# PY32F003xx register map
Vendor: Puya; Series: PY32F0; File version: 1.0.0
CPU: CM0+ r0p1, little endian, no MPU, no FPU, 4 interrupt priority bits
Registers are 32-bit, read-write, reset 0x0 unless marked. A register's access mark holds for its fields unless they carry their own. Offsets are from the block's base; [hi:lo] are bit positions.

## IWDG — Independent watchdog
Base 0x40003000
0x00 KR wo — Key register (IWDG_KR)
  [15:0] KEY — Key value
0x04 PR — Prescaler register (IWDG_PR)
  [2:0] PR — Prescaler divider
    1=0; 2=1; 4=2
0x08 RLR reset 0xFFF — Reload register (IWDG_RLR)
  [11:0] RL — Watchdog counter reloadvalue
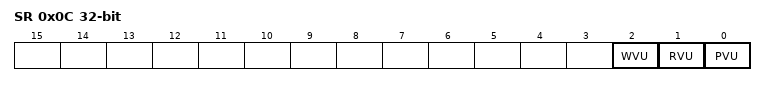
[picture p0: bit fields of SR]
0x0C SR ro — Status register (IWDG_SR)
  [2] WVU — Watchdog counter window value update
  [1] RVU — Watchdog counter reload valueupdate
  [0] PVU — Watchdog prescaler valueupdate
0x10 WINR ro — Window register (IWDG_SR)
  [11:0] WIN — window counter

## LPTIM — Low power timer
Base 0x40007C00
0x00 ISR ro — Interrupt and Status Register
  [1] ARRM — Autoreload match
0x04 ICR wo — Interrupt Clear Register
  [1] ARRMCF — Autoreload match ClearFlag
0x08 IER — Interrupt Enable Register
  [1] ARRMIE — Autoreload match InterruptEnable
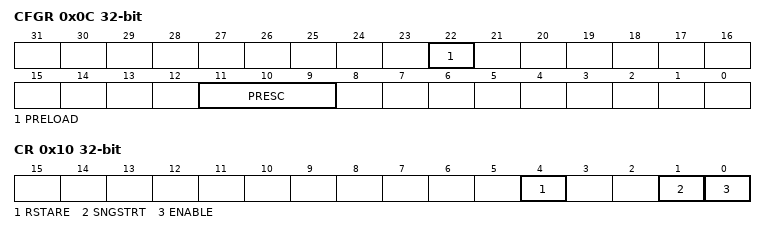
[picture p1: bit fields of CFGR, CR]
0x0C CFGR — Configuration Register
  [22] PRELOAD — Registers update mode
  [11:9] PRESC — Clock prescaler
    1=0; 2=1; 4=2
0x10 CR — Control Register
  [4] RSTARE — Reset after read enable
  [1] SNGSTRT — LPTIM start in single mode
  [0] ENABLE — LPTIM Enable
0x18 ARR reset 0x1 — Autoreload Register
  [15:0] ARR — Auto reload value
0x1C CNT ro — Counter Register
  [15:0] CNT — Counter value

## PWR — Power control
Base 0x40007000
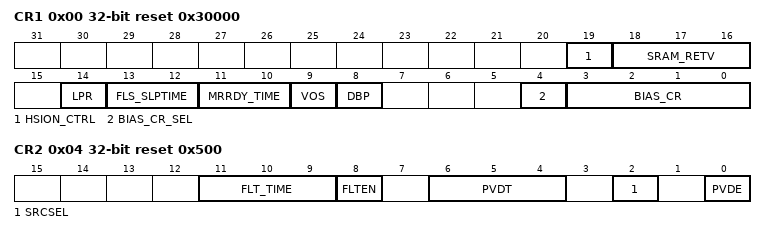
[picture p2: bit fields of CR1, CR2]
0x00 CR1 reset 0x30000 — Power control register 1
  [19] HSION_CTRL — HSI open time control
  [18:16] SRAM_RETV — SRAM retention voltage control
    1=0; 2=1; 4=2
  [14] LPR — Low-power run
  [13:12] FLS_SLPTIME — Flash wait time after wakeup from the stop mode
    1=0; 2=1
  [11:10] MRRDY_TIME — Time selection wakeup from LP to VR
    1=0; 2=1
  [9] VOS — Voltage scaling rangeselection
  [8] DBP — Disable backup domain writeprotection
  [4] BIAS_CR_SEL — MR Bias current selection
  [3:0] BIAS_CR — MR Bias current
    1=0; 2=1; 4=2; 8=3
0x04 CR2 reset 0x500 — Power control register 2
  [11:9] FLT_TIME — Digital filter time configuration
    1=0; 2=1; 4=2
  [8] FLTEN — Digital filter enable
  [6:4] PVDT — Power voltage detector thresholdselection
    1=0; 2=1; 4=2
  [2] SRCSEL — Power voltage detector volatageselection
  [0] PVDE — Power voltage detectorenable
0x14 SR ro — Power status register
  [11] PVDO — PVD output

## RTC — Real time clock
Base 0x40002800
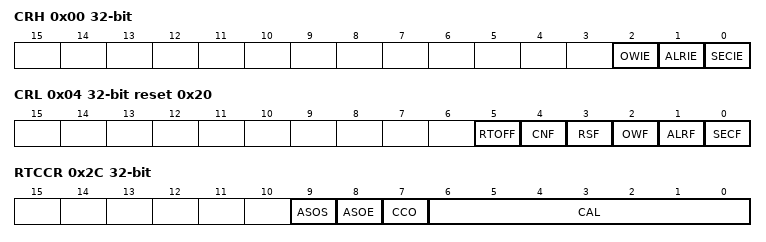
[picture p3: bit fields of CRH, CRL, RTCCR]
0x00 CRH — RTC Control Register High
  [2] OWIE — Overflow interrupt Enable
  [1] ALRIE — Alarm interrupt Enable
  [0] SECIE — Second interrupt Enable
0x04 CRL reset 0x20 — RTC Control Register Low
  [5] RTOFF ro — RTC operation OFF
  [4] CNF — Configuration Flag
  [3] RSF — Registers Synchronized Flag
  [2] OWF — Overflow Flag
  [1] ALRF — Alarm Flag
  [0] SECF — Second Flag
0x08 PRLH wo — RTC Prescaler Load Register High
  [3:0] PRLH
0x0C PRLL wo reset 0x8000 — RTC Prescaler Load Register Low
  [15:0] PRLL — RTC Prescaler Divider Register Low
0x10 DIVH ro — RTC Prescaler Divider Register High
  [3:0] DIVH — RTC prescaler divider register high
0x14 DIVL ro reset 0x8000 — RTC Prescaler Divider Register Low
  [15:0] DIVL — RTC prescaler divider register Low
0x18 CNTH — RTC Counter Register High
  [15:0] CNTH — RTC counter register high
0x1C CNTL — RTC Counter Register Low
  [15:0] CNTL — RTC counter register Low
0x20 ALRH wo reset 0xFFFF — RTC Alarm Register High
  [15:0] ALRH — RTC alarm register high
0x24 ALRL wo reset 0xFFFF — RTC Alarm Register Low
  [15:0] ALRL — RTC alarm register low
0x2C RTCCR — RTC clock calibration
  [9] ASOS — Alarm or second output selection
  [8] ASOE — Alarm or second output enable
  [7] CCO — Calibration clock output
  [6:0] CAL — Calibration value

## SPI1 — Serial peripheral interface
Base 0x40013000
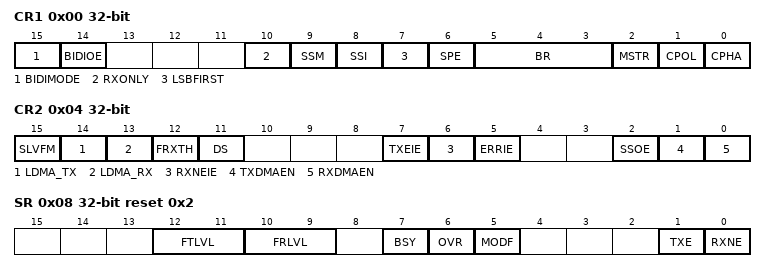
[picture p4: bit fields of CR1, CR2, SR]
0x00 CR1 — control register 1
  [15] BIDIMODE — Bidirectional data mode enable
  [14] BIDIOE — Output enable in bidirectional mode
  [10] RXONLY — Receive only
  [9] SSM — Software slave management
  [8] SSI — Internal slave selection
  [7] LSBFIRST — Frame format
  [6] SPE — SPI enable
  [5:3] BR — Baud rate control
    1=0; 2=1; 4=2
  [2] MSTR — Master selection
  [1] CPOL — Clock polarity
  [0] CPHA — Clock phase
0x04 CR2 — control register 2
  [15] SLVFM — Slave fast mode enable
  [14] LDMA_TX — Last DAM Transmit(TX)
  [13] LDMA_RX — Last DAM Transmit(RX)
  [12] FRXTH — FIFO reception threshold
  [11] DS — Data length
  [7] TXEIE — Tx buffer empty interrupt enable
  [6] RXNEIE — RX buffer not empty interrupt enable
  [5] ERRIE — Error interrupt enable
  [2] SSOE — SS output enable
  [1] TXDMAEN — Tx buffer DMA enable
  [0] RXDMAEN — Rx buffer DMA enable
0x08 SR reset 0x2 — status register
  [12:11] FTLVL ro — FIFO transmission level
    1=0; 2=1
  [10:9] FRLVL ro — FIFO reception level
    1=0; 2=1
  [7] BSY ro — Busy flag
  [6] OVR ro — Overrun flag
  [5] MODF ro — Mode fault
  [1] TXE ro — Transmit buffer empty
  [0] RXNE ro — Receive buffer not empty
0x0C DR — data register
  [15:0] DR — Data register
